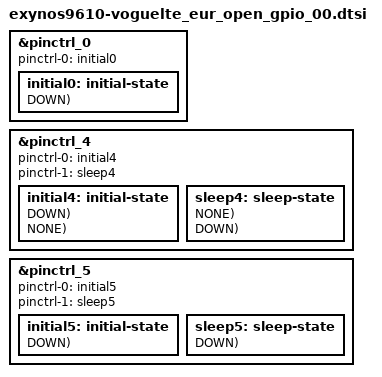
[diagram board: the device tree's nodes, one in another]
/*
 * Copyright (c) 2018 Samsung Electronics Co., Ltd.
 *		http://www.samsung.com
 *
 * This program is free software; you can redistribute it and/or modify
 * it under the terms of the GNU General Public License version 2 as
 * published by the Free Software Foundation.
 */

/* Support Vogue EUR HWREV0.0 (b0000) */

#include "exynos_gpio_config_macros.dtsi"

/*
 * pin banks of exynos9610 pin-controller 0 (ALIVE)
 * ETC0
 * GPA0, GPA1, GPA2
 * GPQ0
 * Note that do not set sleep state because this is an ALIVE region.
 */
&pinctrl_0 {
	pinctrl-names = "default";
	pinctrl-0 = <&initial0>;
	initial0: initial-state {
		PIN_IN(gpa2-5, DOWN);	/* NC */
	};
};

/*
 * pin banks of exynos9610 pin-controller 1 (CMGP)
 * GPM0 ~ 25
 */
/*
&pinctrl_1 {
};
*/

/*
 * pin banks of exynos9610 pin-controller 2 (DISPAUD)
 * GPB0, GPB1, GPB2
 */
/*
&pinctrl_2 {
};
*/

/*
 * pin banks of exynos9610 pin-controller 3 (FSYS)
 * GPF0, GPF1, GPF2
 */
/*
&pinctrl_3 {
};
*/

/*
 * pin banks of exynos9610 pin-controller 4 (TOP)
 * GPP0, GPP1, GPP2
 * GPC0, GPC1, GPC2
 * GPG0, GPG1, GPG2, GPG3, GPG4
 */
&pinctrl_4 {
	pinctrl-names = "default","sleep";
	pinctrl-0 = <&initial4>;
	pinctrl-1 = <&sleep4>;
	initial4: initial-state {
		PIN_IN(gpp0-6, DOWN);	/* NC */
		PIN_IN(gpp0-7, DOWN);	/* NC */

		PIN_IN(gpc2-4, DOWN);	/* NC */

		PIN_IN(gpg0-7, DOWN);	/* NC */
		PIN_IN(gpg1-4, DOWN);	/* NC */

		PIN_IN(gpg3-3, NONE);	/* HW_REV0 */
		PIN_IN(gpg3-4, NONE);	/* HW_REV1 */
		PIN_IN(gpg3-5, NONE);	/* HW_REV2 */
	};
	sleep4: sleep-state {
		PIN_SLP(gpp0-0, INPUT, NONE);	/* CC_SDA_1P8 */
		PIN_SLP(gpp0-1, INPUT, NONE);	/* CC_SCL_1P8 */
		PIN_SLP(gpp0-2, INPUT, NONE);	/* IF_PMIC_SDA_1P8 */
		PIN_SLP(gpp0-3, INPUT, NONE);	/* IF_PMIC_SCL_1P8 */
		PIN_SLP(gpp0-4, INPUT, NONE);	/* NFC_SDA_1P8 */
		PIN_SLP(gpp0-5, INPUT, NONE);	/* NFC_SCL_1P8 */
		PIN_SLP(gpp0-6, INPUT, DOWN);	/* NC */
		PIN_SLP(gpp0-7, INPUT, DOWN);	/* NC */

		PIN_SLP(gpp1-0, INPUT, NONE);	/* TSP_SDA_1P8 */
		PIN_SLP(gpp1-1, INPUT, NONE);	/* TSP_SCL_1P8 */
		PIN_SLP(gpp1-2, INPUT, NONE);	/* GRIP_SDA_1P8 */
		PIN_SLP(gpp1-3, INPUT, NONE);	/* GRIP_SCL_1P8 */
		PIN_SLP(gpp1-4, INPUT, NONE);	/* CODEC_SDA_1P8 */
		PIN_SLP(gpp1-5, INPUT, NONE);	/* CODEC_SCL_1P8 */

		PIN_SLP(gpc1-2, INPUT, DOWN);	/* NC */
		PIN_SLP(gpc1-3, INPUT, DOWN);	/* NC */

		PIN_SLP(gpc2-2, INPUT, DOWN);	/* NC */
		PIN_SLP(gpc2-4, INPUT, DOWN);	/* NC */

		PIN_SLP(gpg0-7, INPUT, DOWN);	/* NC */
		PIN_SLP(gpg1-2, PREV, NONE);	/* LCD_EN_1P8 */
		PIN_SLP(gpg1-3, PREV, NONE);	/* OLED_RST_N */
		PIN_SLP(gpg1-4, INPUT, DOWN);	/* NC */

		PIN_SLP(gpg2-2, PREV, NONE);	/* LCD_VDDR_EN */
		PIN_SLP(gpg2-4, PREV, NONE);	/* LCD_EN_3P0 */

		PIN_SLP(gpg3-3, INPUT, NONE);	/* HW_REV0 */
		PIN_SLP(gpg3-4, INPUT, NONE);	/* HW_REV1 */
		PIN_SLP(gpg3-5, INPUT, NONE);	/* HW_REV2 */
	};
};

/*
 * pin banks of exynos9610 pin-controller 5 (SHUB)
 * GPH0, GPH1
 */
&pinctrl_5 {
	pinctrl-names = "default","sleep";
	pinctrl-0 = <&initial5>;
	pinctrl-1 = <&sleep5>;
	initial5: initial-state {
		PIN_IN(gph1-0, DOWN);	/* NC */
		PIN_IN(gph1-1, DOWN);	/* NC */
		PIN_IN(gph1-2, DOWN);	/* NC */
	};
	sleep5: sleep-state {
		PIN_SLP(gph1-0, INPUT, DOWN);	/* NC */
		PIN_SLP(gph1-1, INPUT, DOWN);	/* NC */
		PIN_SLP(gph1-2, INPUT, DOWN);	/* NC */
	};
};
